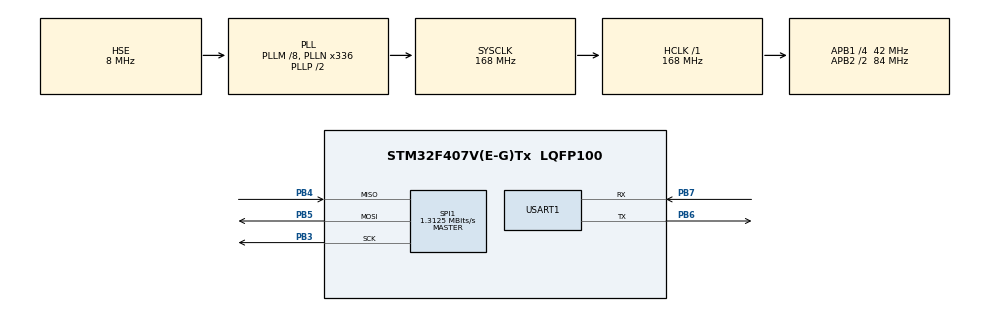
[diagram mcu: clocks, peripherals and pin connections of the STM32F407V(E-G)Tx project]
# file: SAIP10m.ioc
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Mcu.Family=STM32F4
Mcu.Name=STM32F407V(E-G)Tx
Mcu.Package=LQFP100
NVIC.PriorityGroup=NVIC_PRIORITYGROUP_0
PB3.Mode=Full_Duplex_Master
PB3.Signal=SPI1_SCK
PB4.Mode=Full_Duplex_Master
PB4.Signal=SPI1_MISO
PB5.Mode=Full_Duplex_Master
PB5.Signal=SPI1_MOSI
PB6.Mode=Asynchronous
PB6.Signal=USART1_TX
PB7.Mode=Asynchronous
PB7.Signal=USART1_RX
PH0-OSC_IN.Mode=HSE-External-Oscillator
PH0-OSC_IN.Signal=RCC_OSC_IN
PH1-OSC_OUT.Mode=HSE-External-Oscillator
PH1-OSC_OUT.Signal=RCC_OSC_OUT
ProjectManager.HeapSize=0x200
ProjectManager.StackSize=0x400
ProjectManager.TargetToolchain=EWARM V8.32
RCC.48MHZClocksFreq_Value=48000000
RCC.AHBFreq_Value=168000000
RCC.APB1CLKDivider=RCC_HCLK_DIV4
RCC.APB1Freq_Value=42000000
RCC.APB1TimFreq_Value=84000000
RCC.APB2CLKDivider=RCC_HCLK_DIV2
RCC.APB2Freq_Value=84000000
RCC.APB2TimFreq_Value=168000000
RCC.CortexFreq_Value=168000000
RCC.HCLKFreq_Value=168000000
RCC.HSE_VALUE=8000000
RCC.HSI_VALUE=16000000
RCC.LSE_VALUE=32768
RCC.PLLM=8
RCC.PLLN=336
RCC.PLLQ=7
RCC.PLLSourceVirtual=RCC_PLLSOURCE_HSE
RCC.SYSCLKFreq_VALUE=168000000
RCC.SYSCLKSource=RCC_SYSCLKSOURCE_PLLCLK
RCC.VCOOutputFreq_Value=336000000
SPI1.BaudRatePrescaler=SPI_BAUDRATEPRESCALER_64
SPI1.CalculateBaudRate=1.3125 MBits/s
SPI1.Direction=SPI_DIRECTION_2LINES
SPI1.Mode=SPI_MODE_MASTER
SPI1.VirtualType=VM_MASTER
USART1.VirtualMode=VM_ASYNC
board=STM32F407G-DISC1

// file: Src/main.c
/* USER CODE BEGIN Header */
/**
  ******************************************************************************
  * @file           : main.c
  * @brief          : Main program body
  ******************************************************************************
  * @attention
  *
  * <h2><center>&copy; Copyright (c) 2020 STMicroelectronics.
  * All rights reserved.</center></h2>
  *
  * This software component is licensed by ST under BSD 3-Clause license,
  * the "License"; You may not use this file except in compliance with the
  * License. You may obtain a copy of the License at:
  *                        opensource.org/licenses/BSD-3-Clause
  *
  ******************************************************************************
  */
/* USER CODE END Header */

#include "main.h"

SPI_HandleTypeDef hspi1;

UART_HandleTypeDef huart1;

/* USER CODE BEGIN PV */
uint8_t RxData[5],TxData[5]="Adc01";
/* USER CODE END PV */

void SystemClock_Config(void);
static void MX_GPIO_Init(void);
static void MX_SPI1_Init(void);
static void MX_USART1_UART_Init(void);

int main(void)
{

  /* MCU Configuration--------------------------------------------------------*/

  /* Reset of all peripherals, Initializes the Flash interface and the Systick. */
  HAL_Init();

  /* Configure the system clock */
  SystemClock_Config();

  /* Initialize all configured peripherals */
  MX_GPIO_Init();
  MX_SPI1_Init();
  MX_USART1_UART_Init();

  /* Infinite loop */
  /* USER CODE BEGIN WHILE */
  while (1)
  {
    HAL_SPI_TransmitReceive(&hspi1, (uint8_t *) TxData,(uint8_t *) RxData,5,100);
    HAL_UART_Transmit(&huart1, (uint8_t *)RxData, 5,10);
    HAL_Delay(500);
    /* USER CODE END WHILE */

  }
}

void SystemClock_Config(void)
{
  RCC_OscInitTypeDef RCC_OscInitStruct = {0};
  RCC_ClkInitTypeDef RCC_ClkInitStruct = {0};

  /** Configure the main internal regulator output voltage
  */
  __HAL_RCC_PWR_CLK_ENABLE();
  __HAL_PWR_VOLTAGESCALING_CONFIG(PWR_REGULATOR_VOLTAGE_SCALE1);
  /** Initializes the CPU, AHB and APB busses clocks
  */
  RCC_OscInitStruct.OscillatorType = RCC_OSCILLATORTYPE_HSE;
  RCC_OscInitStruct.HSEState = RCC_HSE_ON;
  RCC_OscInitStruct.PLL.PLLState = RCC_PLL_ON;
  RCC_OscInitStruct.PLL.PLLSource = RCC_PLLSOURCE_HSE;
  RCC_OscInitStruct.PLL.PLLM = 8;
  RCC_OscInitStruct.PLL.PLLN = 336;
  RCC_OscInitStruct.PLL.PLLP = RCC_PLLP_DIV2;
  RCC_OscInitStruct.PLL.PLLQ = 7;
  if (HAL_RCC_OscConfig(&RCC_OscInitStruct) != HAL_OK)
  {
    Error_Handler();
  }
  /** Initializes the CPU, AHB and APB busses clocks
  */
  RCC_ClkInitStruct.ClockType = RCC_CLOCKTYPE_HCLK|RCC_CLOCKTYPE_SYSCLK
                              |RCC_CLOCKTYPE_PCLK1|RCC_CLOCKTYPE_PCLK2;
  RCC_ClkInitStruct.SYSCLKSource = RCC_SYSCLKSOURCE_PLLCLK;
  RCC_ClkInitStruct.AHBCLKDivider = RCC_SYSCLK_DIV1;
  RCC_ClkInitStruct.APB1CLKDivider = RCC_HCLK_DIV4;
  RCC_ClkInitStruct.APB2CLKDivider = RCC_HCLK_DIV2;

  if (HAL_RCC_ClockConfig(&RCC_ClkInitStruct, FLASH_LATENCY_5) != HAL_OK)
  {
    Error_Handler();
  }
}

static void MX_SPI1_Init(void)
{

  /* SPI1 parameter configuration*/
  hspi1.Instance = SPI1;
  hspi1.Init.Mode = SPI_MODE_MASTER;
  hspi1.Init.Direction = SPI_DIRECTION_2LINES;
  hspi1.Init.DataSize = SPI_DATASIZE_8BIT;
  hspi1.Init.CLKPolarity = SPI_POLARITY_LOW;
  hspi1.Init.CLKPhase = SPI_PHASE_1EDGE;
  hspi1.Init.NSS = SPI_NSS_SOFT;
  hspi1.Init.BaudRatePrescaler = SPI_BAUDRATEPRESCALER_64;
  hspi1.Init.FirstBit = SPI_FIRSTBIT_MSB;
  hspi1.Init.TIMode = SPI_TIMODE_DISABLE;
  hspi1.Init.CRCCalculation = SPI_CRCCALCULATION_DISABLE;
  hspi1.Init.CRCPolynomial = 10;
  if (HAL_SPI_Init(&hspi1) != HAL_OK)
  {
    Error_Handler();
  }

}

static void MX_USART1_UART_Init(void)
{

  huart1.Instance = USART1;
  huart1.Init.BaudRate = 115200;
  huart1.Init.WordLength = UART_WORDLENGTH_8B;
  huart1.Init.StopBits = UART_STOPBITS_1;
  huart1.Init.Parity = UART_PARITY_NONE;
  huart1.Init.Mode = UART_MODE_TX_RX;
  huart1.Init.HwFlowCtl = UART_HWCONTROL_NONE;
  huart1.Init.OverSampling = UART_OVERSAMPLING_16;
  if (HAL_UART_Init(&huart1) != HAL_OK)
  {
    Error_Handler();
  }

}

static void MX_GPIO_Init(void)
{

  /* GPIO Ports Clock Enable */
  __HAL_RCC_GPIOH_CLK_ENABLE();
  __HAL_RCC_GPIOB_CLK_ENABLE();

}

void Error_Handler(void)
{
}

/************************ (C) COPYRIGHT STMicroelectronics *****END OF FILE****/
